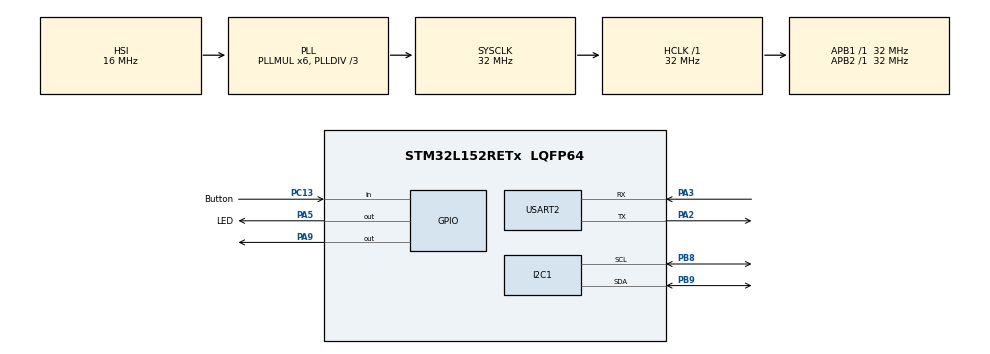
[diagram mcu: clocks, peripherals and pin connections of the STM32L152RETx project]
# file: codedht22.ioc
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Mcu.Family=STM32L1
Mcu.Name=STM32L152RETx
Mcu.Package=LQFP64
NVIC.PriorityGroup=NVIC_PRIORITYGROUP_0
PA2.Mode=Asynchronous
PA2.Signal=USART2_TX
PA3.Mode=Asynchronous
PA3.Signal=USART2_RX
PA5.GPIO_Label=LED
PA5.Signal=GPIO_Output
PA9.Signal=GPIO_Output
PB8.Mode=I2C
PB8.Signal=I2C1_SCL
PB9.Mode=I2C
PB9.Signal=I2C1_SDA
PC13-WKUP2.GPIO_Label=Button
PC13-WKUP2.Signal=GPIO_Input
ProjectManager.HeapSize=0x200
ProjectManager.StackSize=0x400
ProjectManager.TargetToolchain=MDK-ARM V5.27
RCC.48MHZClocksFreq_Value=48000000
RCC.AHBFreq_Value=32000000
RCC.APB1Freq_Value=32000000
RCC.APB1TimFreq_Value=32000000
RCC.APB2Freq_Value=32000000
RCC.APB2TimFreq_Value=32000000
RCC.HCLKFreq_Value=32000000
RCC.HSE_VALUE=8000000
RCC.HSI_VALUE=16000000
RCC.LSE_VALUE=32768
RCC.MSI_VALUE=2097000
RCC.PLLDIV=RCC_PLL_DIV3
RCC.PLLMUL=RCC_PLL_MUL6
RCC.RTCClockSelectionVirtual=RCC_RTCCLKSOURCE_LSE
RCC.SYSCLKFreq_VALUE=32000000
RCC.SYSCLKSource=RCC_SYSCLKSOURCE_PLLCLK
RCC.USBOutput=48000000
RCC.VCOOutputFreq_Value=96000000
USART2.VirtualMode=VM_ASYNC
board=NUCLEO-L152RE

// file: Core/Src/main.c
/* USER CODE BEGIN Header */

/* USER CODE END Header */
#include "main.h"
#include "i2c.h"
#include "usart.h"
#include "gpio.h"

/* USER CODE BEGIN Includes */
#include "MY_DHT22.h"
#include <lib_lcd.h>
/* USER CODE END Includes */

void SystemClock_Config(void);

/* USER CODE BEGIN 0 */
float TempC, Humidity;
char uartData[50];

/* USER CODE END 0 */

int main(void)
{

  /* MCU Configuration--------------------------------------------------------*/

  /* Reset of all peripherals, Initializes the Flash interface and the Systick. */
  HAL_Init();

  /* Configure the system clock */
  SystemClock_Config();

  /* Initialize all configured peripherals */
  MX_GPIO_Init();
  MX_USART2_UART_Init();
  MX_I2C1_Init();
  /* USER CODE BEGIN 2 */
  DHT22_Init(GPIOA, GPIO_PIN_9);

  /* USER CODE END 2 */

  /* Infinite loop */
  while (1)
  {

    /* USER CODE BEGIN 3 */

		/*if(DHT22_GetTemp_Humidity(&TempC, &Humidity) == 1)
		{

			//sprintf(uartData, "\r\nTemp (C) =\t %.1f\r\nHumidity (%%) =\t %.1f%%\r\n", TempC, Humidity);

			/*sprintf(uartData, "Temp (C) = %.1f", TempC);
			lcd_position(&hi2c1,0,0);
			lcd_print(&hi2c1, uartData);

			sprintf(uartData, "Humidity (%%) = %.1f%%", Humidity);
			lcd_position(&hi2c1,1,0);
			lcd_print(&hi2c1, uartData);

			HAL_UART_Transmit(&huart2, (uint8_t *)uartData, strlen(uartData), 10);

		}
		else
		{
			sprintf(uartData, "\r\nCRC Error!\r\n");
			HAL_UART_Transmit(&huart2, (uint8_t *)uartData, strlen(uartData), 10);
		}
		*/

		DHT22_GetTemp_Humidity(&TempC, &Humidity);

		  lcd_position(&hi2c1,8,0);
			sprintf(uartData, "Temp (C) = %.1f", TempC);
			lcd_print(&hi2c1, uartData);

		   lcd_position(&hi2c1,8,1);
			//sprintf(uartData, "Humidity (%%) = %.1f%%", Humidity);
			//lcd_print(&hi2c1, uartData);

	HAL_UART_Transmit(&huart2, (uint8_t *)uartData, strlen(uartData), 10);

		//lcd_print(&hi2c1, uartData);

		HAL_Delay(500);

  }
  /* USER CODE END 3 */
}

void SystemClock_Config(void)
{
  RCC_OscInitTypeDef RCC_OscInitStruct = {0};
  RCC_ClkInitTypeDef RCC_ClkInitStruct = {0};

  /** Configure the main internal regulator output voltage
  */
  __HAL_PWR_VOLTAGESCALING_CONFIG(PWR_REGULATOR_VOLTAGE_SCALE1);
  /** Initializes the RCC Oscillators according to the specified parameters
  * in the RCC_OscInitTypeDef structure.
  */
  RCC_OscInitStruct.OscillatorType = RCC_OSCILLATORTYPE_HSI;
  RCC_OscInitStruct.HSIState = RCC_HSI_ON;
  RCC_OscInitStruct.HSICalibrationValue = RCC_HSICALIBRATION_DEFAULT;
  RCC_OscInitStruct.PLL.PLLState = RCC_PLL_ON;
  RCC_OscInitStruct.PLL.PLLSource = RCC_PLLSOURCE_HSI;
  RCC_OscInitStruct.PLL.PLLMUL = RCC_PLL_MUL6;
  RCC_OscInitStruct.PLL.PLLDIV = RCC_PLL_DIV3;
  if (HAL_RCC_OscConfig(&RCC_OscInitStruct) != HAL_OK)
  {
    Error_Handler();
  }
  /** Initializes the CPU, AHB and APB buses clocks
  */
  RCC_ClkInitStruct.ClockType = RCC_CLOCKTYPE_HCLK|RCC_CLOCKTYPE_SYSCLK
                              |RCC_CLOCKTYPE_PCLK1|RCC_CLOCKTYPE_PCLK2;
  RCC_ClkInitStruct.SYSCLKSource = RCC_SYSCLKSOURCE_PLLCLK;
  RCC_ClkInitStruct.AHBCLKDivider = RCC_SYSCLK_DIV1;
  RCC_ClkInitStruct.APB1CLKDivider = RCC_HCLK_DIV1;
  RCC_ClkInitStruct.APB2CLKDivider = RCC_HCLK_DIV1;

  if (HAL_RCC_ClockConfig(&RCC_ClkInitStruct, FLASH_LATENCY_1) != HAL_OK)
  {
    Error_Handler();
  }
}

void Error_Handler(void)
{
}

/************************ (C) COPYRIGHT STMicroelectronics *****END OF FILE****/
